# nrf5340_application register map
Vendor: Nordic Semiconductor; Series: nrf53; File version: 1
CPU: CM33 r0p4, little endian, MPU, FPU, 3 interrupt priority bits, 69 interrupts
Registers are 32-bit, read-write, reset 0x0 unless marked. A register's access mark holds for its fields unless they carry their own. Offsets are from the block's base; [hi:lo] are bit positions; {n}, {i} and the like mark numbered series; 'fields as' and 'values as' point back to an identical list.

## CC_AES_S — CRYPTOCELL AES engine
Base 0x50845000
{0x400+4i} AES_KEY_0[{i}] (i=0..7) wo — Description collection: AES key value to use in non-tunneling operations, or as the first tunnel stage key in tunneling operations. The initial AES_KEY_0[0] register holds the least significant bits [31:0] of the key value.
  [31:0] VALUE — AES non-tunneling or first tunnel stage key value.
{0x420+4i} AES_KEY_1[{i}] (i=0..7) wo — Description collection: AES key value to use as the second tunnel stage key in tunneling operations. The initial AES_KEY_1[0] register holds the least significant bits [31:0] of the key value.
  [31:0] VALUE — AES second tunnel stage key value.
{0x440+4i} AES_IV_0[{i}] (i=0..3) — Description collection: AES Initialization Vector (IV) to use in non-tunneling operations, or as the first tunnel stage IV in tunneling operations. The initial AES_IV_0[0] register holds the least significant bits [31:0] of the IV.
  [31:0] VALUE — AES non-tunneling or first tunnel stage IV value.
{0x450+4i} AES_IV_1[{i}] (i=0..3) — Description collection: AES Initialization Vector (IV) to use as the second tunnel stage IV in tunneling operations. The initial AES_IV_1[0] register holds the least significant bits [31:0] of the IV.
  [31:0] VALUE — AES second tunnel stage IV value.
{0x460+4i} AES_CTR[{i}] (i=0..3) — Description collection: AES counter (CTR) to use in non-tunneling and tunneling operations. The initial AES_CTR[0] register holds the least significant bits [31:0] of the CTR.
  [31:0] VALUE — AES CTR value.
0x470 AES_BUSY ro — Status register for AES engine activity.
  [0] STATUS — AES engine status.
    0=Idle (AES engine is idle); 1=Busy (AES engine is busy)
0x47C AES_CMAC_INIT wo — Writing to this address triggers the AES engine to generate K1 and K2 for AES-CMAC operations.
  [0] ENABLE — Generate K1 and K2 for the AES-CMAC operations.
    1=Enable (Initialize AES-CMAC operations.)
0x4BC AES_REMAINING_BYTES — This register should be set with the amount of remaining bytes until the end of the current AES operation.
  [31:0] VALUE — Remaining bytes util the end of the current AES operation.
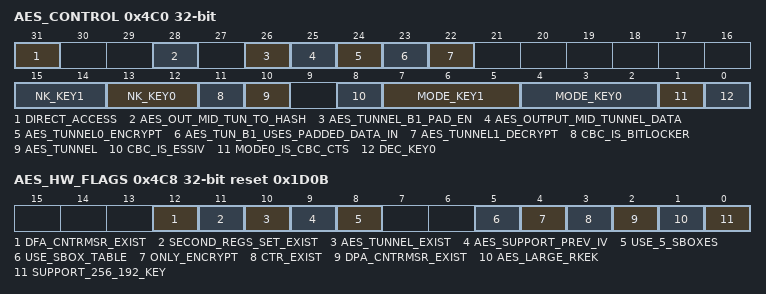
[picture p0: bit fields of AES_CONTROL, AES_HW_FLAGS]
0x4C0 AES_CONTROL — Control the AES engine behavior.
  [31] DIRECT_ACCESS — Using direct access and not the DIN-DOUT DMA interface
    0=Disable (Access using the DIN-DOUT DMA interface); 1=Enable (Access using direct access)
  [28] AES_OUT_MID_TUN_TO_HASH — This field determines for AES-TO-HASH-AND-DOUT tunneling operations, whether the AES outputs to the HASH the result of the first or the second tunneling stage.
    0=SecondStage (The AES engine writes to the HASH the result of the second tunnel stage.); 1=FirstStage (The AES engine writes to the HASH the result of the first tunnel stage.)
  [26] AES_TUNNEL_B1_PAD_EN — This field configure if the input data to the second tunnel stage is to be padded with zeroes according to how many bytes are remaining.
    0=Disable (The data input to the second tunnel stage is not padded with zeros.); 1=Enable (The data input to the second tunnel stage is padded with zeros.)
  [25] AES_OUTPUT_MID_TUNNEL_DATA — This fields configure if the AES engine output is the result of the first or second tunneling stage.
    0=SecondStage (Output result from the second tunnel stage (standard tunneling).); 1=FirstStage (Output result from the first tunnel stage.)
  [24] AES_TUNNEL0_ENCRYPT — Configure if first tunnel stage performs encrypt or decrypt operation.
    0=Decrypt (First tunnel stage performs decrypt operations.); 1=Encrypt (First tunnel stage performs encrypt operations.)
  [23] AES_TUN_B1_USES_PADDED_DATA_IN — For tunneling operations this field determine the data that is fed to the second tunneling stage.
    0=Disable (The output of the first block is used directly (standard tunneling operation).); 1=Enable (The output of the first block is padded before use.)
  [22] AES_TUNNEL1_DECRYPT — Configure if first tunnel stage performs encrypt or decrypt operation.
    0=Encrypt (Second tunnel stage performs encrypt operations.); 1=Decrypt (Second tunnel stage performs decrypt operations.)
  [15:14] NK_KEY1 — Set the AES key length of the second stage in tunneling operations.
    0=128 bits key length; 1=192 bits key length; 2=256 bits key length
  [13:12] NK_KEY0 — Set the AES key length in non-tunneling operations, or the AES key length of the first stage in tunneling operations.
    values as NK_KEY1
  [11] CBC_IS_BITLOCKER — If MODE_KEY0 is set to CBC, and this field is set, the mode is CBC Bitlocker.
    0=Disable CBC Bitlocker mode; 1=Enable CBC Bitlocker mode
  [10] AES_TUNNEL — Configure AES engine for standard non-tunneling or tunneling operations.
    0=Disable (Standard non-tunneling operations); 1=Enable tunneling operations
  [8] CBC_IS_ESSIV — If MODE_KEY0 is set to CBC, and this field is set, the mode is CBC with ESSIV.
    0=Disable CBC with ESSIV mode; 1=Enable CBC with ESSIV mode
  [7:5] MODE_KEY1 — Set the AES mode of the second stage in tunneling operations
    0=ECB (Electronic codebook mode); 1=CBC (Cipher block chaining mode); 2=CTR (Counter mode); 3=CBC_MAC (Cipher block chaining message authentication code mode); 4=XEX_XTS (Xor-Encrypt-Xor (XEX)-based tweaked-codebook mode with ciphertext stealing (XTS)); 5=XCBC_MAC (AES in CBC mode with extensions to overcome fixed length limitations); 6=OFB (AES Output FeedBack mode); 7=CMAC (Cipher-based Message Authentication Code)
  [4:2] MODE_KEY0 — Set the AES mode in non-tunneling operations, or the AES mode of the first stage in tunneling operations.
    0=ECB (Electronic codebook mode); 1=CBC (Cipher block chaining mode); 2=CTR (Counter mode); 3=CBC_MAC (Cipher Block Chaining Message Authentication Code); 4=XEX_XTS (Xor-Encrypt-Xor (XEX)-based tweaked-codebook mode with ciphertext stealing (XTS)); 5=XCBC_MAC (AES in CBC mode with extensions to overcome fixed length limitations); 6=OFB (AES Output FeedBack mode); 7=CMAC (Cipher-based Message Authentication Code)
  [1] MODE0_IS_CBC_CTS — This field allows to add distinction to the CBC and CTR modes defined in field MODE_KEY0. If MODE_KEY0 is set to CBC in combination with this field, AES mode is CBC-CTS. If MODE_KEY0 is set to CTR in combination with this field, AES mode is GCTR.
    0=Disable CBC-CTS and GCTR mode; 1=Enable CBC-CTS and GCTR mode
  [0] DEC_KEY0 — Set AES encrypt or decrypt mode in non-tunneling operations.
    0=Encrypt (Perform AES encryption); 1=Decrypt (Perform AES decryption)
0x4C8 AES_HW_FLAGS ro reset 0x1D0B — Hardware configuration of the AES engine. Reset value holds the supported features.
  [12] DFA_CNTRMSR_EXIST — If this flag is set, the engine support DFA countermeasures.
  [11] SECOND_REGS_SET_EXIST — If this flag is set, the engine support a second register set for tunneling operations.
  [10] AES_TUNNEL_EXIST — If this flag is set, the engine support tunneling operations.
  [9] AES_SUPPORT_PREV_IV — If this flag is set, the engine contains the PREV_IV register for faster AES XCBC MAC calculation.
  [8] USE_5_SBOXES — If this flag is set, the engine uses 5 SBOX where each AES round takes 4 cycles.
  [5] USE_SBOX_TABLE — If this flag is set, the engine uses SBOX tables.
  [4] ONLY_ENCRYPT — If this flag is set, the engine only support encrypt operations.
  [3] CTR_EXIST — If this flag is set, the engine support AES CTR mode.
  [2] DPA_CNTRMSR_EXIST — If this flag is set, the engine support DPA countermeasures.
  [1] AES_LARGE_RKEK — If this flag is set, the engine support AES_LARGE_RKEK.
  [0] SUPPORT_256_192_KEY — If this flag is set, the engine support 192 bits and 256 bits key size.
0x4D8 AES_CTR_NO_INCREMENT — This register enables the AES CTR no increment mode in which the counter mode is not incremented between two blocks
  [0] ENABLE — This field enables the AES CTR no increment mode in which the counter mode is not incremented between two blocks
    0=Disable (Counter always incremented between blocks); 1=Enable (Do not increment counter between blocks)
0x4F4 AES_SW_RESET wo — Reset the AES engine.
  [0] RESET — Writing any value to this address resets the AES engine. The reset takes 4 CPU clock cycles to complete.
    1=Enable (Reset AES engine.)
0x524 AES_CMAC_SIZE0_KICK wo — Writing to this address triggers the AES engine to perform a CMAC operation with size 0. The CMAC result can be read from the AES_IV_0 register.
  [0] ENABLE — Force AES CMAC operation with size 0.
    0=Disable (Normal AES CMAC operation); 1=Enable (Force CMAC operation with size 0)
